# max32570 register map
Vendor: Maxim-Integrated; Series: ARMCM4; File version: 1.0
CPU: CM4 r2p1, little endian, MPU, FPU, 3 interrupt priority bits
Registers are 32-bit, read-write, reset 0x0 unless marked. A register's access mark holds for its fields unless they carry their own. Offsets are from the block's base; [hi:lo] are bit positions; 'fields as' and 'values as' point back to an identical list.

## TRIMSIR — Trim System Initilazation Registers
Base 0x40005400
0x00 rsv0 — RFU
0x08 BB_SIR2 ro — System Init. Configuration Register 2.
0x0C BB_SIR3 ro — System Init. Configuration Register 3.

## TRNG — Random Number Generator.
Base 0x4004D000
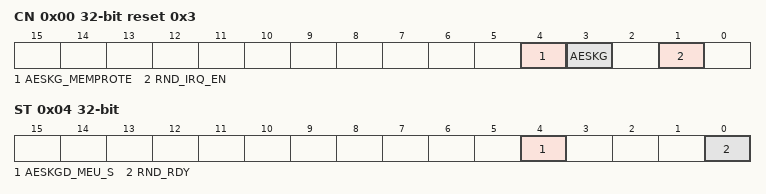
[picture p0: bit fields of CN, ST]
0x00 CN reset 0x3 — TRNG Control Register.
  [4] AESKG_MEMPROTE — AES Key Generate. When enabled, the key for securing NVSRAM is generated and transferred to the secure key register automatically without user visibility or intervention. This bit is cleared by hardware once the key has been transferred to the secure key register.
  [3] AESKG — AES Key Generate.
  [1] RND_IRQ_EN — To enable IRQ generation when a new 32-bit Random number is ready.
    0=disable; 1=enable
0x04 ST ro — Data. The content of this register is valid only when RNG_IS = 1. When TRNG is disabled, read returns 0x0000 0000.
  [4] AESKGD_MEU_S — Automatically AES transfer on going
  [0] RND_RDY — 32-bit random data is ready to read from TRNG_DATA register. Reading TRNG_DATA when RND_RDY=0 will return all 0's. IRQ is generated when RND_RDY=1 if TRNG_CN.RND_IRQ_EN=1.
    0=Busy (TRNG Busy); 1=Ready (32 bit random data is ready)
0x08 DATA ro — Data. The content of this register is valid only when RNG_IS = 1. When TRNG is disabled, read returns 0x0000 0000.
  [31:0] DATA — Data. The content of this register is valid only when RNG_IS =1. When TNRG is disabled, read returns 0x0000 0000.

## WDT0 — Watchdog Timer 0
Base 0x40003000
Same registers: WDT1 0x40003400
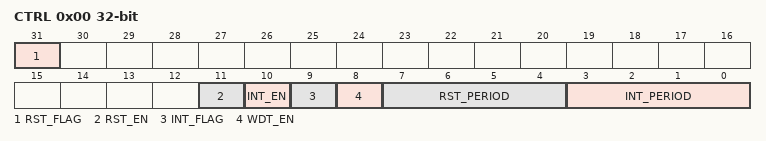
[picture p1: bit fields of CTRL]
0x00 CTRL (reset mask 0x7FFFF000) — Watchdog Timer Control Register.
  [31] RST_FLAG — Watchdog Timer Reset Flag.
    0=noEvent (The event has not occurred.); 1=occurred (The event has occurred.)
  [11] RST_EN — Watchdog Timer Reset Enable.
    0=dis (Disable.); 1=en (Enable.)
  [10] INT_EN — Watchdog Timer Interrupt Enable.
    0=dis (Disable.); 1=en (Enable.)
  [9] INT_FLAG write-1-clears — Watchdog Timer Interrupt Flag.
    0=inactive (No interrupt is pending.); 1=pending (An interrupt is pending.)
  [8] WDT_EN — Watchdog Timer Enable.
    0=dis (Disable.); 1=en (Enable.)
  [7:4] RST_PERIOD — Watchdog Reset Period. The watchdog timer will assert a reset, if enabled, if the CPU does not write the watchdog reset sequence to the WDT_RST register before the watchdog timer has counted this time period since the last timer reset.
    0=wdt2pow31 (2**31 clock cycles.); 1=wdt2pow30 (2**30 clock cycles.); 2=wdt2pow29 (2**29 clock cycles.); 3=wdt2pow28 (2**28 clock cycles.); 4=wdt2pow27 (2^27 clock cycles.); 5=wdt2pow26 (2**26 clock cycles.); 6=wdt2pow25 (2**25 clock cycles.); 7=wdt2pow24 (2**24 clock cycles.); 8=wdt2pow23 (2**23 clock cycles.); 9=wdt2pow22 (2**22 clock cycles.); 10=wdt2pow21 (2**21 clock cycles.); 11=wdt2pow20 (2**20 clock cycles.); 12=wdt2pow19 (2**19 clock cycles.); 13=wdt2pow18 (2**18 clock cycles.); 14=wdt2pow17 (2**17 clock cycles.); 15=wdt2pow16 (2**16 clock cycles.)
  [3:0] INT_PERIOD — Watchdog Interrupt Period. The watchdog timer will assert an interrupt, if enabled, if the CPU does not write the watchdog reset sequence to the WDT_RST register before the watchdog timer has counted this time period since the last timer reset.
    values as RST_PERIOD
0x04 RST wo — Watchdog Timer Reset Register.
  [7:0] WDT_RST — Writing the watchdog counter 'reset sequence' to this register resets the watchdog counter. If the watchdog count exceeds INT_PERIOD then a watchdog interrupt will occur, if enabled. If the watchdog count exceeds RST_PERIOD then a watchdog reset will occur, if enabled.
    165=seq0 (The first value to be written to reset the WDT.); 90=seq1 (The second value to be written to reset the WDT.)
